# STM32H7P5xx register map
File version: 1.0
Registers are 32-bit, read-write, reset 0x0 unless marked. A register's access mark holds for its fields unless they carry their own. Offsets are from the block's base; [hi:lo] are bit positions; {n}, {i} and the like mark numbered series.

## TIM2 — General Purpose Timer
Base 0x40000000
Same registers: TIM3 0x40000400, TIM4 0x40000800, TIM5 0x40000C00
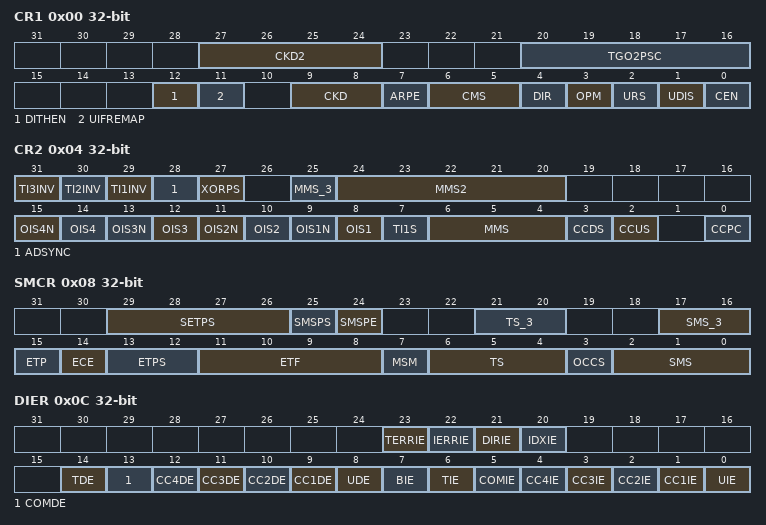
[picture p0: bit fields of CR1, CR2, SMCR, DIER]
0x00 CR1 — TIM control register 1
  [27:24] CKD2 — Clock division 2
  [20:16] TGO2PSC — Trigger output 2 postcaler
  [12] DITHEN — Dithering enable
  [11] UIFREMAP — UIF status bit remapping
  [9:8] CKD — Clock division
  [7] ARPE — Autoreload preload enable
  [6:5] CMS — Center-aligned mode selection
  [4] DIR — Direction
  [3] OPM — One-pulse mode
  [2] URS — Update request source
  [1] UDIS — Update disable
  [0] CEN — Counter enable
0x04 CR2 — TIM control register 2
  [31] TI3INV — tim_ti3 signal inversion on XOR gate input
  [30] TI2INV — tim_ti2 signal inversion on XOR gate input
  [29] TI1INV — tim_ti1 signal inversion on XOR gate input
  [28] ADSYNC — ADC synchronization
  [27] XORPS — XOR gate position selection
  [25] MMS_3 — MMS[2:0]: Master mode selection
  [24:20] MMS2 — Master mode selection 2
  [2n+7] OIS{n}N (n=1..4) — Output idle state {n} (tim_oc{n}n output)
  [14] OIS4 — Output idle state 4 (tim_oc4 output)
  [12] OIS3 — Output idle state 3 (tim_oc3n output)
  [10] OIS2 — Output idle state 2 (tim_oc2 output)
  [8] OIS1 — Output idle state 1 (tim_oc1 output)
  [7] TI1S — tim_ti1 selection
  [6:4] MMS — MMS[2:0]: Master mode selection
  [3] CCDS — Capture/compare DMA selection
  [2] CCUS — Capture/compare control update selection
  [0] CCPC — Capture/compare preloaded control
0x08 SMCR — TIM slave mode control register
  [29:26] SETPS — Synchronous external trigger prescaler
  [25] SMSPS — SMS preload source
  [24] SMSPE — SMS preload enable
  [21:20] TS_3 — TS[2:0]: Trigger selection
  [17:16] SMS_3 — SMS[2:0]: Slave mode selection
  [15] ETP — External trigger polarity
  [14] ECE — External clock enable
  [13:12] ETPS — External trigger prescaler
  [11:8] ETF — External trigger filter
  [7] MSM — Master/slave mode
  [6:4] TS — TS[2:0]: Trigger selection
  [3] OCCS — OCREF clear selection
  [2:0] SMS — SMS[2:0]: Slave mode selection
0x0C DIER — TIM DMA/interrupt enable register
  [23] TERRIE — Transition error interrupt enable
  [22] IERRIE — Index error interrupt enable
  [21] DIRIE — Direction change interrupt enable
  [20] IDXIE — Index interrupt enable
  [14] TDE — Trigger DMA request enable
  [13] COMDE — COM DMA request enable
  [n+8] CC{n}DE (n=1..4) — Capture/compare {n} DMA request enable
  [8] UDE — Update DMA request enable
  [7] BIE — Break interrupt enable
  [6] TIE — Trigger interrupt enable
  [5] COMIE — COM interrupt enable
  [n] CC{n}IE (n=1..4) — Capture/compare {n} interrupt enable
  [0] UIE — Update interrupt enable
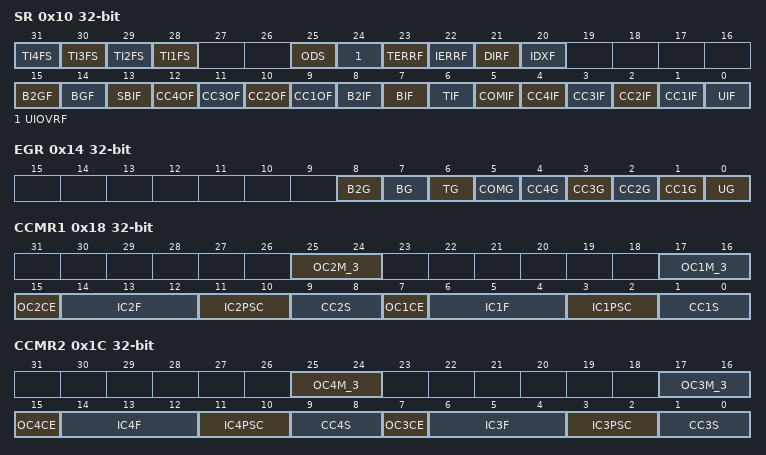
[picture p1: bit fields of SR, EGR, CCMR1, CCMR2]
0x10 SR — TIM status register
  [n+27] TI{n}FS (n=1..4) — tim_ti{n}f status
  [25] ODS — Output disable status
  [24] UIOVRF — Update Interrupt Overrun flag
  [23] TERRF — Transition error interrupt flag
  [22] IERRF — Index error interrupt flag
  [21] DIRF — Direction change interrupt flag
  [20] IDXF — Index interrupt flag
  [15] B2GF — Break 2 generation flag
  [14] BGF — Break generation flag
  [13] SBIF — System break interrupt flag
  [n+8] CC{n}OF (n=1..4) — Capture/compare {n} overcapture flag
  [8] B2IF — Break 2 interrupt flag
  [7] BIF — Break interrupt flag
  [6] TIF — Trigger interrupt flag
  [5] COMIF — COM interrupt flag
  [n] CC{n}IF (n=1..4) — Capture/compare {n} interrupt flag
  [0] UIF — Update interrupt flag
0x14 EGR — TIM event generation register
  [8] B2G — Break 2 generation
  [7] BG — Break generation
  [6] TG — Trigger generation
  [5] COMG — Capture/compare control update generation
  [n] CC{n}G (n=1..4) — Capture/compare {n} generation
  [0] UG — Update generation
0x18 CCMR1 — TIM capture/compare mode register 1
  [25:24] OC2M_3 — OC2M[2:0] bits (Output compare 2 mode)
  [17:16] OC1M_3 — OC1M[2:0] bits (Output compare 1 mode)
  [15] OC2CE — OC2CE (Output compare 2 clear enable)
  [14:12] IC2F — Input capture 2 filter
  [11:10] IC2PSC — Input capture 2 prescaler
  [9:8] CC2S — Capture/compare 2 selection
  [7] OC1CE — OC1CE (Output compare 1 clear enable)
  [6:4] IC1F — Input capture 1 filter
  [3:2] IC1PSC — Input capture 1 prescaler
  [1:0] CC1S — Capture/compare 1 Selection
0x1C CCMR2 — TIM capture/compare mode register 2
  [25:24] OC4M_3 — OC4M[2:0] bits (Output compare 4 mode)
  [17:16] OC3M_3 — OC3M[2:0] bits (Output compare 3 mode)
  [15] OC4CE — OC4CE (Output compare 4 clear enable)
  [14:12] IC4F — Input capture 4 filter
  [11:10] IC4PSC — Input capture 4 prescaler
  [9:8] CC4S — Capture/compare 4 selection
  [7] OC3CE — OC3CE (Output compare 3 clear enable)
  [6:4] IC3F — Input capture 3 filter
  [3:2] IC3PSC — Input capture 3 prescaler
  [1:0] CC3S — Capture/compare 3 selection
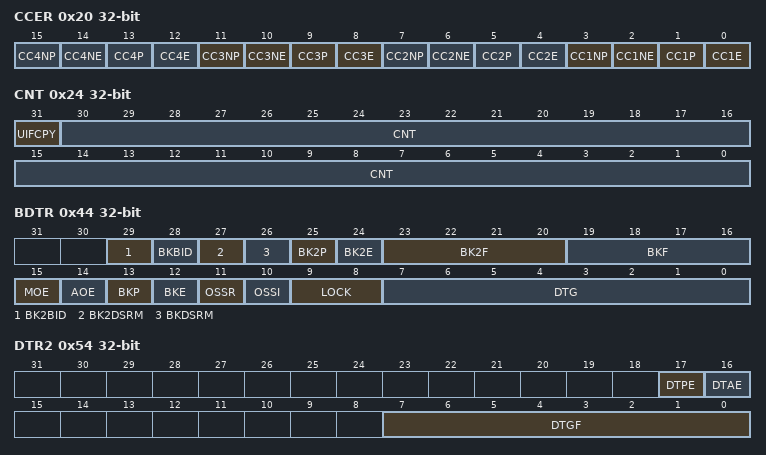
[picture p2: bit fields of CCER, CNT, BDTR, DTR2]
0x20 CCER — TIM capture/compare enable register
  [4n-1] CC{n}NP (n=1..4) — Capture/compare {n} complementary output polarity
  [4n-2] CC{n}NE (n=1..4) — Capture/compare {n} complementary output enable
  [4n-3] CC{n}P (n=1..4) — Capture/compare {n} output polarity
  [4n-4] CC{n}E (n=1..4) — Capture/compare {n} output enable
0x24 CNT — TIM counter
  [31] UIFCPY — UIF copy
  [30:0] CNT — Counter value
0x28 PSC — TIM prescaler
  [15:0] PSC — Prescaler value
0x2C ARR — TIM autoreload register
  [31:0] ARR — Autoreload value
0x30 RCR — TIM repetition counter register
  [15:0] REP — Repetition counter reload value
0x34 CCR1 — TIM capture/compare register 1
  [31:0] CCR1 — Capture/compare 1 value
0x38 CCR2 — TIM capture/compare register 2
  [31:0] CCR2 — Capture/compare 2 value
0x3C CCR3 — TIM capture/compare register 3
  [31:0] CCR3 — Capture/compare value
0x40 CCR4 — TIM capture/compare register 4
  [31:0] CCR4 — Capture/compare value
0x44 BDTR — TIM break and dead-time register
  [29] BK2BID — Break2 bidirectional
  [28] BKBID — Break bidirectional
  [27] BK2DSRM — Break2 disarm
  [26] BKDSRM — Break disarm
  [25] BK2P — Break 2 polarity
  [24] BK2E — Break 2 enable
  [23:20] BK2F — Break 2 filter
  [19:16] BKF — Break filter
  [15] MOE — Main output enable
  [14] AOE — Automatic output enable
  [13] BKP — Break polarity
  [12] BKE — Break enable
  [11] OSSR — Off-state selection for Run mode
  [10] OSSI — Off-state selection for idle mode
  [9:8] LOCK — Lock configuration
  [7:0] DTG — Dead-time generator setup
0x54 DTR2 — TIM timer deadtime register 2
  [17] DTPE — Deadtime preload enable
  [16] DTAE — Deadtime asymmetric enable
  [7:0] DTGF — Dead-time falling edge generator setup
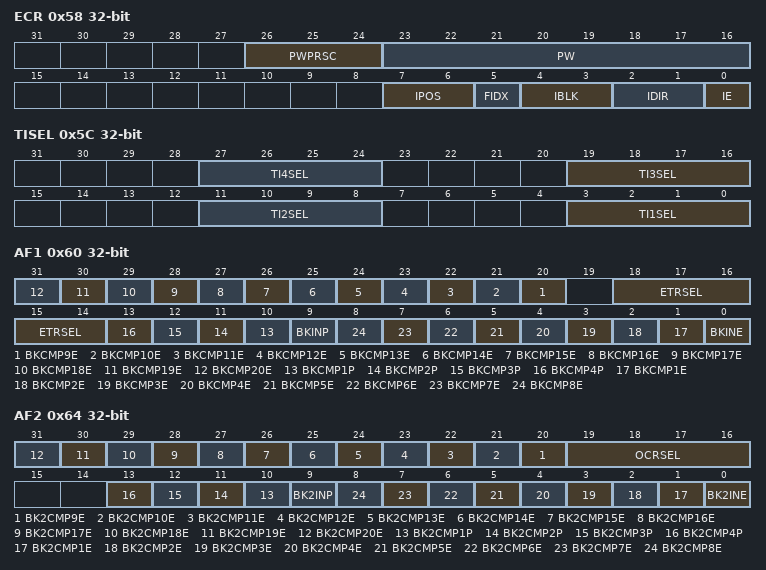
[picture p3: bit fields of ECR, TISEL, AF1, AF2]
0x58 ECR — TIM timer encoder control register
  [26:24] PWPRSC — Pulse width prescaler
  [23:16] PW — Pulse width
  [7:6] IPOS — Index positioning
  [5] FIDX — First index
  [4:3] IBLK — Index blanking
  [2:1] IDIR — Index direction
  [0] IE — Index enable
0x5C TISEL — TIM timer input selection register
  [8n-5:8n-8] TI{n}SEL (n=1..4) — Selects tim_ti{n}[15:0] input
0x60 AF1 — TIM alternate function option register 1
  [n+11] BKCMP{n}E (n=9..20) — tim_brk_cmp{n} enable
  [18:14] ETRSEL — etr_in source selection
  [n+9] BKCMP{n}P (n=1..4) — tim_brk_cmp{n} input polarity
  [9] BKINP — TIMx_BKIN input polarity
  [n] BKCMP{n}E (n=1..8) — tim_brk_cmp{n} enable
  [0] BKINE — TIMx_BKIN input enable
0x64 AF2 — TIM alternate function register 2
  [n+11] BK2CMP{n}E (n=9..20) — tim_brk2_cmp{n} enable
  [19:16] OCRSEL — ocref_clr source selection
  [n+9] BK2CMP{n}P (n=1..4) — tim_brk2_cmp{n} input polarity
  [9] BK2INP — TIMx_BKIN2 input polarity
  [n] BK2CMP{n}E (n=1..8) — tim_brk2_cmp{n} enable
  [0] BK2INE — TIMx_BKIN2 input enable
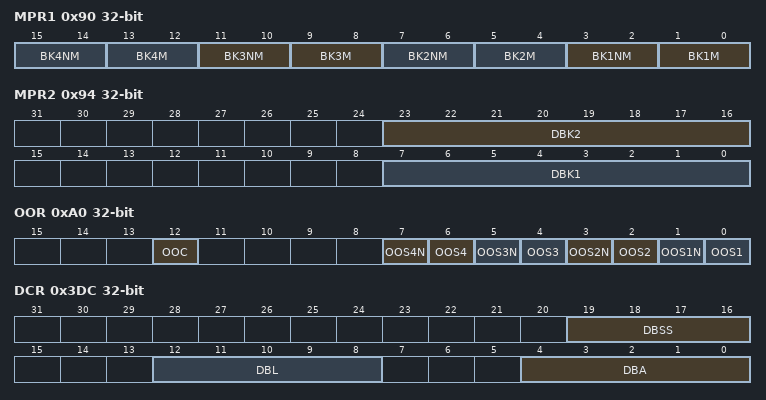
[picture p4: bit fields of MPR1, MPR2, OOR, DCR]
0x90 MPR1 — TIM multilevel protection register 1
  [4n-1:4n-2] BK{n}NM (n=1..4) — Break mode for tim_oc{n}n output
  [4n-3:4n-4] BK{n}M (n=1..4) — Break mode for tim_oc{n} output
0x94 MPR2 — TIM multilevel protection register 2
  [23:16] DBK2 — Delayed 2 Break duration
  [7:0] DBK1 — Delayed 1 Break duration
0xA0 OOR — TIM output override register
  [12] OOC — Output override control
  [2n-1] OOS{n}N (n=1..4) — Output override state for output tim_oc{n}n
  [2n-2] OOS{n} (n=1..4) — Output override state for output tim_oc{n}
0x3DC DCR — TIM DMA control register
  [19:16] DBSS — DMA burst source selection
  [12:8] DBL — DMA burst length
  [4:0] DBA — DMA base address
0x3E0 DMAR — TIM DMA address for full transfer
  [31:0] DMAB — DMA register for burst accesses

## TIM6 — General Purpose Timer
Base 0x40001000
Same registers: TIM7 0x40001400
Registers as TIM2, without CCMR1, CCMR2, CCER, CCR{n} (n=1..4); these are added or differ:
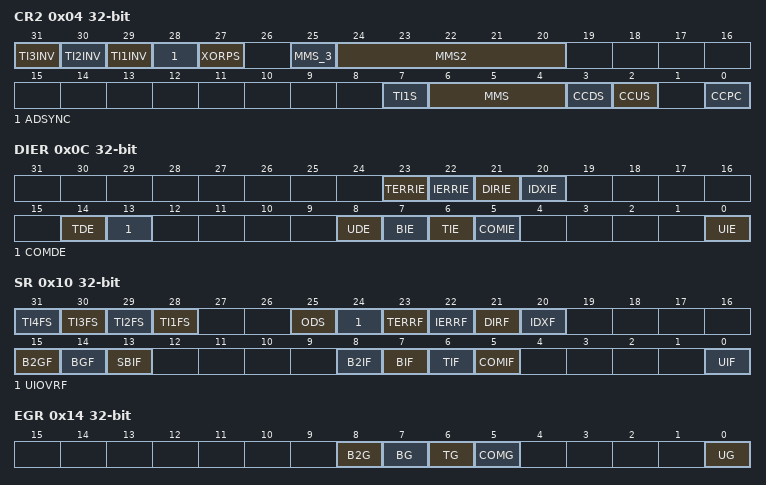
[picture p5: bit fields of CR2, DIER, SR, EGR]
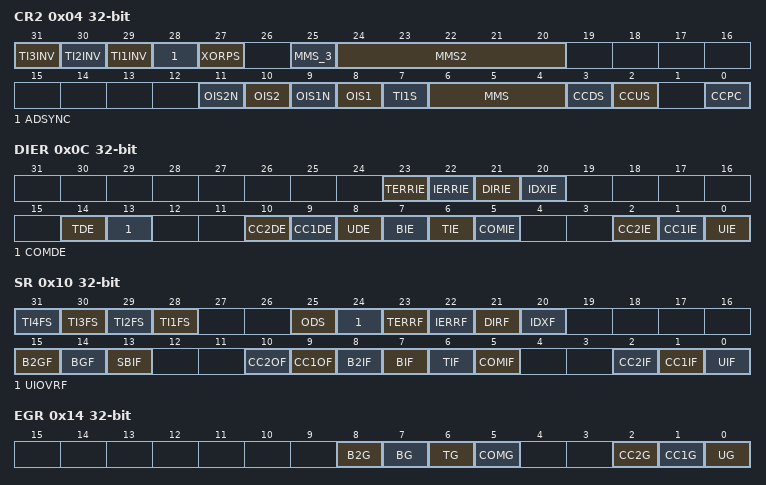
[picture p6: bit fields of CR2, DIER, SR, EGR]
0x04 CR2 — TIM control register 2
  [31] TI3INV — tim_ti3 signal inversion on XOR gate input
  [30] TI2INV — tim_ti2 signal inversion on XOR gate input
  [29] TI1INV — tim_ti1 signal inversion on XOR gate input
  [28] ADSYNC — ADC synchronization
  [27] XORPS — XOR gate position selection
  [25] MMS_3 — MMS[2:0]: Master mode selection
  [24:20] MMS2 — Master mode selection 2
  [7] TI1S — tim_ti1 selection
  [6:4] MMS — MMS[2:0]: Master mode selection
  [3] CCDS — Capture/compare DMA selection
  [2] CCUS — Capture/compare control update selection
  [0] CCPC — Capture/compare preloaded control
0x0C DIER — TIM DMA/interrupt enable register
  [23] TERRIE — Transition error interrupt enable
  [22] IERRIE — Index error interrupt enable
  [21] DIRIE — Direction change interrupt enable
  [20] IDXIE — Index interrupt enable
  [14] TDE — Trigger DMA request enable
  [13] COMDE — COM DMA request enable
  [8] UDE — Update DMA request enable
  [7] BIE — Break interrupt enable
  [6] TIE — Trigger interrupt enable
  [5] COMIE — COM interrupt enable
  [0] UIE — Update interrupt enable
0x10 SR — TIM status register
  [n+27] TI{n}FS (n=1..4) — tim_ti{n}f status
  [25] ODS — Output disable status
  [24] UIOVRF — Update Interrupt Overrun flag
  [23] TERRF — Transition error interrupt flag
  [22] IERRF — Index error interrupt flag
  [21] DIRF — Direction change interrupt flag
  [20] IDXF — Index interrupt flag
  [15] B2GF — Break 2 generation flag
  [14] BGF — Break generation flag
  [13] SBIF — System break interrupt flag
  [8] B2IF — Break 2 interrupt flag
  [7] BIF — Break interrupt flag
  [6] TIF — Trigger interrupt flag
  [5] COMIF — COM interrupt flag
  [0] UIF — Update interrupt flag
0x14 EGR — TIM event generation register
  [8] B2G — Break 2 generation
  [7] BG — Break generation
  [6] TG — Trigger generation
  [5] COMG — Capture/compare control update generation
  [0] UG — Update generation

## TIM12 — General Purpose Timer
Base 0x40001800
Same registers: TIM15 0x42004000, TIM9 0x42004C00
Registers as TIM2, without CCMR2, CCR3, CCR4; these are added or differ:
0x04 CR2 — TIM control register 2
  [31] TI3INV — tim_ti3 signal inversion on XOR gate input
  [30] TI2INV — tim_ti2 signal inversion on XOR gate input
  [29] TI1INV — tim_ti1 signal inversion on XOR gate input
  [28] ADSYNC — ADC synchronization
  [27] XORPS — XOR gate position selection
  [25] MMS_3 — MMS[2:0]: Master mode selection
  [24:20] MMS2 — Master mode selection 2
  [11] OIS2N — Output idle state 2 (tim_oc2n output)
  [10] OIS2 — Output idle state 2 (tim_oc2 output)
  [9] OIS1N — Output idle state 1 (tim_oc1n output)
  [8] OIS1 — Output idle state 1 (tim_oc1 output)
  [7] TI1S — tim_ti1 selection
  [6:4] MMS — MMS[2:0]: Master mode selection
  [3] CCDS — Capture/compare DMA selection
  [2] CCUS — Capture/compare control update selection
  [0] CCPC — Capture/compare preloaded control
0x0C DIER — TIM DMA/interrupt enable register
  [23] TERRIE — Transition error interrupt enable
  [22] IERRIE — Index error interrupt enable
  [21] DIRIE — Direction change interrupt enable
  [20] IDXIE — Index interrupt enable
  [14] TDE — Trigger DMA request enable
  [13] COMDE — COM DMA request enable
  [10] CC2DE — Capture/compare 2 DMA request enable
  [9] CC1DE — Capture/compare 1 DMA request enable
  [8] UDE — Update DMA request enable
  [7] BIE — Break interrupt enable
  [6] TIE — Trigger interrupt enable
  [5] COMIE — COM interrupt enable
  [2] CC2IE — Capture/compare 2 interrupt enable
  [1] CC1IE — Capture/compare 1 interrupt enable
  [0] UIE — Update interrupt enable
0x10 SR — TIM status register
  [n+27] TI{n}FS (n=1..4) — tim_ti{n}f status
  [25] ODS — Output disable status
  [24] UIOVRF — Update Interrupt Overrun flag
  [23] TERRF — Transition error interrupt flag
  [22] IERRF — Index error interrupt flag
  [21] DIRF — Direction change interrupt flag
  [20] IDXF — Index interrupt flag
  [15] B2GF — Break 2 generation flag
  [14] BGF — Break generation flag
  [13] SBIF — System break interrupt flag
  [10] CC2OF — Capture/compare 2 overcapture flag
  [9] CC1OF — Capture/compare 1 overcapture flag
  [8] B2IF — Break 2 interrupt flag
  [7] BIF — Break interrupt flag
  [6] TIF — Trigger interrupt flag
  [5] COMIF — COM interrupt flag
  [2] CC2IF — Capture/compare 2 interrupt flag
  [1] CC1IF — Capture/compare 1 interrupt flag
  [0] UIF — Update interrupt flag
0x14 EGR — TIM event generation register
  [8] B2G — Break 2 generation
  [7] BG — Break generation
  [6] TG — Trigger generation
  [5] COMG — Capture/compare control update generation
  [2] CC2G — Capture/compare 2 generation
  [1] CC1G — Capture/compare 1 generation
  [0] UG — Update generation
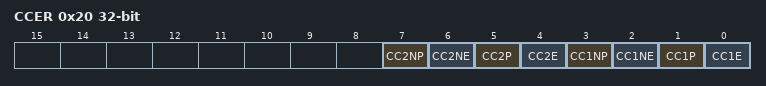
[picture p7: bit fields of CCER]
0x20 CCER — TIM capture/compare enable register
  [7] CC2NP — Capture/compare 2 complementary output polarity
  [6] CC2NE — Capture/compare 2 complementary output enable
  [5] CC2P — Capture/compare 2 output polarity
  [4] CC2E — Capture/compare 2 output enable
  [3] CC1NP — Capture/compare 1 complementary output polarity
  [2] CC1NE — Capture/compare 1 complementary output enable
  [1] CC1P — Capture/compare 1 output polarity
  [0] CC1E — Capture/compare 1 output enable

## TIM13 — General Purpose Timer
Base 0x40001C00
Same registers: TIM14 0x40002000, TIM10 0x40003000, TIM11 0x40003400, TIM16 0x42004400, TIM17 0x42004800
Registers as TIM2, without CCMR2, CCR{n} (n=2..4); these are added or differ:
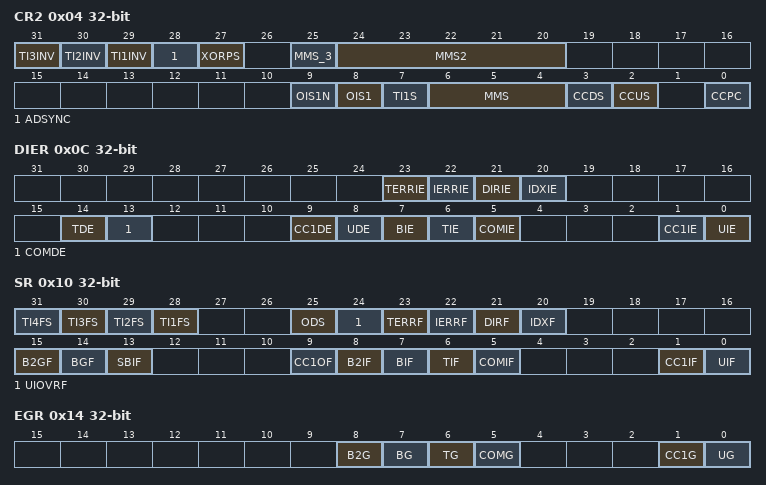
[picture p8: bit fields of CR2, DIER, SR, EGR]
0x04 CR2 — TIM control register 2
  [31] TI3INV — tim_ti3 signal inversion on XOR gate input
  [30] TI2INV — tim_ti2 signal inversion on XOR gate input
  [29] TI1INV — tim_ti1 signal inversion on XOR gate input
  [28] ADSYNC — ADC synchronization
  [27] XORPS — XOR gate position selection
  [25] MMS_3 — MMS[2:0]: Master mode selection
  [24:20] MMS2 — Master mode selection 2
  [9] OIS1N — Output idle state 1 (tim_oc1n output)
  [8] OIS1 — Output idle state 1 (tim_oc1 output)
  [7] TI1S — tim_ti1 selection
  [6:4] MMS — MMS[2:0]: Master mode selection
  [3] CCDS — Capture/compare DMA selection
  [2] CCUS — Capture/compare control update selection
  [0] CCPC — Capture/compare preloaded control
0x0C DIER — TIM DMA/interrupt enable register
  [23] TERRIE — Transition error interrupt enable
  [22] IERRIE — Index error interrupt enable
  [21] DIRIE — Direction change interrupt enable
  [20] IDXIE — Index interrupt enable
  [14] TDE — Trigger DMA request enable
  [13] COMDE — COM DMA request enable
  [9] CC1DE — Capture/compare 1 DMA request enable
  [8] UDE — Update DMA request enable
  [7] BIE — Break interrupt enable
  [6] TIE — Trigger interrupt enable
  [5] COMIE — COM interrupt enable
  [1] CC1IE — Capture/compare 1 interrupt enable
  [0] UIE — Update interrupt enable
0x10 SR — TIM status register
  [n+27] TI{n}FS (n=1..4) — tim_ti{n}f status
  [25] ODS — Output disable status
  [24] UIOVRF — Update Interrupt Overrun flag
  [23] TERRF — Transition error interrupt flag
  [22] IERRF — Index error interrupt flag
  [21] DIRF — Direction change interrupt flag
  [20] IDXF — Index interrupt flag
  [15] B2GF — Break 2 generation flag
  [14] BGF — Break generation flag
  [13] SBIF — System break interrupt flag
  [9] CC1OF — Capture/compare 1 overcapture flag
  [8] B2IF — Break 2 interrupt flag
  [7] BIF — Break interrupt flag
  [6] TIF — Trigger interrupt flag
  [5] COMIF — COM interrupt flag
  [1] CC1IF — Capture/compare 1 interrupt flag
  [0] UIF — Update interrupt flag
0x14 EGR — TIM event generation register
  [8] B2G — Break 2 generation
  [7] BG — Break generation
  [6] TG — Trigger generation
  [5] COMG — Capture/compare control update generation
  [1] CC1G — Capture/compare 1 generation
  [0] UG — Update generation
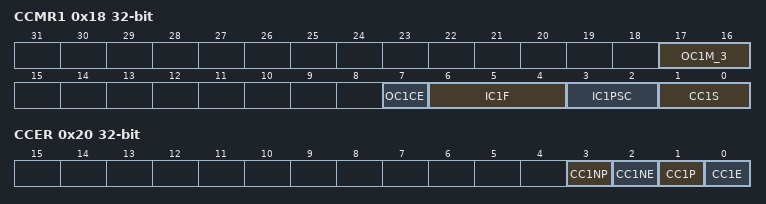
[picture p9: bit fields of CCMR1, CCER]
0x18 CCMR1 — TIM capture/compare mode register 1
  [17:16] OC1M_3 — OC1M[2:0] bits (Output compare 1 mode)
  [7] OC1CE — OC1CE (Output compare 1 clear enable)
  [6:4] IC1F — Input capture 1 filter
  [3:2] IC1PSC — Input capture 1 prescaler
  [1:0] CC1S — Capture/compare 1 Selection
0x20 CCER — TIM capture/compare enable register
  [3] CC1NP — Capture/compare 1 complementary output polarity
  [2] CC1NE — Capture/compare 1 complementary output enable
  [1] CC1P — Capture/compare 1 output polarity
  [0] CC1E — Capture/compare 1 output enable

## TIM1 — General Purpose Timer
Base 0x42000000
Same registers: TIM8 0x42000400, TIM20 0x42000800
Registers as TIM2; these are added or differ:
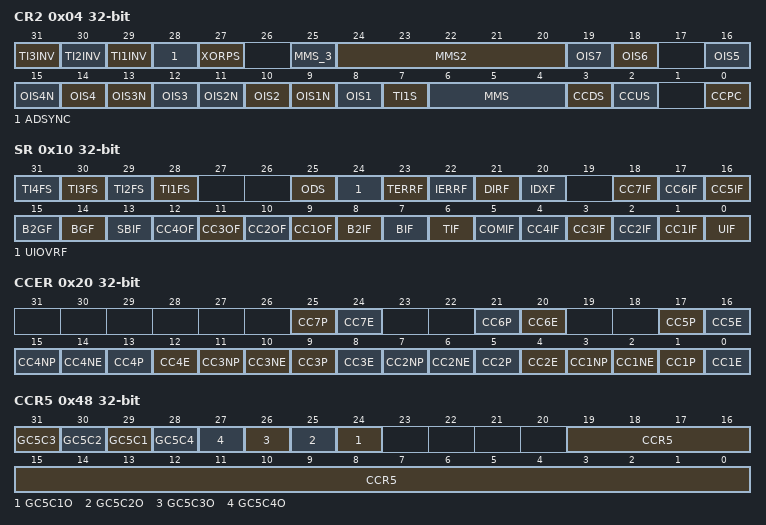
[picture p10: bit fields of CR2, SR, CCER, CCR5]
0x04 CR2 — TIM control register 2
  [31] TI3INV — tim_ti3 signal inversion on XOR gate input
  [30] TI2INV — tim_ti2 signal inversion on XOR gate input
  [29] TI1INV — tim_ti1 signal inversion on XOR gate input
  [28] ADSYNC — ADC synchronization
  [27] XORPS — XOR gate position selection
  [25] MMS_3 — MMS[2:0]: Master mode selection
  [24:20] MMS2 — Master mode selection 2
  [19] OIS7 — Output idle state 7 (tim_oc7 output)
  [18] OIS6 — Output idle state 6 (tim_oc6 output)
  [16] OIS5 — Output idle state 5 (tim_oc5 output)
  [2n+7] OIS{n}N (n=1..4) — Output idle state {n} (tim_oc{n}n output)
  [14] OIS4 — Output idle state 4 (tim_oc4 output)
  [12] OIS3 — Output idle state 3 (tim_oc3n output)
  [10] OIS2 — Output idle state 2 (tim_oc2 output)
  [8] OIS1 — Output idle state 1 (tim_oc1 output)
  [7] TI1S — tim_ti1 selection
  [6:4] MMS — MMS[2:0]: Master mode selection
  [3] CCDS — Capture/compare DMA selection
  [2] CCUS — Capture/compare control update selection
  [0] CCPC — Capture/compare preloaded control
0x10 SR — TIM status register
  [n+27] TI{n}FS (n=1..4) — tim_ti{n}f status
  [25] ODS — Output disable status
  [24] UIOVRF — Update Interrupt Overrun flag
  [23] TERRF — Transition error interrupt flag
  [22] IERRF — Index error interrupt flag
  [21] DIRF — Direction change interrupt flag
  [20] IDXF — Index interrupt flag
  [18] CC7IF — Compare 7 interrupt flag
  [17] CC6IF — Compare 6 interrupt flag
  [16] CC5IF — Compare 5 interrupt flag
  [15] B2GF — Break 2 generation flag
  [14] BGF — Break generation flag
  [13] SBIF — System break interrupt flag
  [n+8] CC{n}OF (n=1..4) — Capture/compare {n} overcapture flag
  [8] B2IF — Break 2 interrupt flag
  [7] BIF — Break interrupt flag
  [6] TIF — Trigger interrupt flag
  [5] COMIF — COM interrupt flag
  [n] CC{n}IF (n=1..4) — Capture/compare {n} interrupt flag
  [0] UIF — Update interrupt flag
0x20 CCER — TIM capture/compare enable register
  [4n-3] CC{n}P (n=1..7) — Capture/compare {n} output polarity
  [4n-4] CC{n}E (n=1..7) — Capture/compare {n} output enable
  [4n-1] CC{n}NP (n=1..4) — Capture/compare {n} complementary output polarity
  [4n-2] CC{n}NE (n=1..4) — Capture/compare {n} complementary output enable
0x48 CCR5 — TIM capture/compare register 5
  [31] GC5C3 — Group channel 5 and channel 3
  [30] GC5C2 — Group channel 5 and channel 2
  [29] GC5C1 — Group channel 5 and channel 1
  [28] GC5C4 — Group channel 5 and channel 4
  [n+23] GC5C{n}O (n=1..4) — Group channel 5 and channel {n} (ORed)
  [19:0] CCR5 — compare 5 value
0x4C CCR6 — TIM capture/compare register 6
  [19:0] CCR6 — Compare 6 value
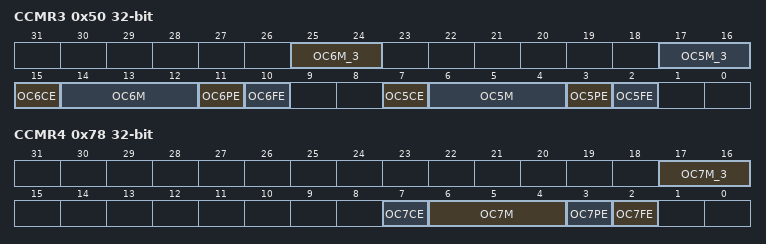
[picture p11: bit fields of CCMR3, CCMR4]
0x50 CCMR3 — TIM capture/compare mode register 3
  [25:24] OC6M_3 — OC6M[2:0]: Output compare 6 mode
  [17:16] OC5M_3 — OC5M[2:0]: Output compare 5 mode
  [15] OC6CE — Output compare 6 clear enable
  [14:12] OC6M — OC6M[2:0]: Output compare 6 mode
  [11] OC6PE — Output compare 6 preload enable
  [10] OC6FE — Output compare 6 fast enable
  [7] OC5CE — Output compare 5 clear enable
  [6:4] OC5M — OC5M[2:0]: Output compare 5 mode
  [3] OC5PE — Output compare 5 preload enable
  [2] OC5FE — Output compare 5 fast enable
0x70 CCR7 — TIM capture/compare register 7
  [19:0] CCR7 — Capture/compare 7 value
0x78 CCMR4 — TIM capture/compare mode register 4
  [17:16] OC7M_3 — OC7M[2:0]: Output compare 7 mode
  [7] OC7CE — Output compare 7 clear enable
  [6:4] OC7M — OC7M[2:0]: Output compare 7 mode
  [3] OC7PE — Output compare 7 preload enable
  [2] OC7FE — Output compare 7 fast enable
